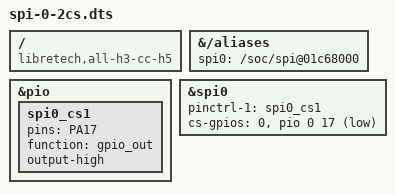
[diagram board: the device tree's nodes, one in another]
// SPDX-License-Identifier: (GPL-2.0+ OR MIT)
/*
 * Copyright (c) 2023 Da Xue <da@libre.computer>
 * Author: Da Xue <da@libre.computer>
 */

/* 40P GPIO
 * Pin 19 MOSI
 * Pin 21 MISO
 * Pin 23 CLK
 * Pin 24 CE0
 * Pin 26 CE1
 */

/dts-v1/;
/plugin/;

#include <dt-bindings/gpio/gpio.h>

/ {
	compatible = "libretech,all-h3-cc-h5", "libretech,all-h3-cc-h3", "allwinner,sun50i-h5", "allwinner,sun8i-h3";

	fragment@0 {
		target-path = "/aliases";
		__overlay__ {
			spi0 = "/soc/spi@01c68000";
		};
	};

	fragment@1 {
		target = <&pio>;
		__overlay__ {
			spi0_cs1: spi0_cs1 {
				pins = "PA17";
				function = "gpio_out";
				output-high;
			};
		};
	};

	fragment@2 {
		target = <&spi0>;
		__overlay__ {
			status = "okay";
			pinctrl-names = "default", "default";
			pinctrl-1 = <&spi0_cs1>;
			cs-gpios = <0>, <&pio 0 17 GPIO_ACTIVE_LOW>;
		};
	};
};
